# MCXA133 register map
Vendor: nxp.com; File version: 1.0
CPU: CM33 r2p0, little endian, no MPU, no FPU, VTOR, 3 interrupt priority bits
Registers are 32-bit, read-write, reset 0x0 unless marked. A register's access mark holds for its fields unless they carry their own. Offsets are from the block's base; [hi:lo] are bit positions; {n}, {i} and the like mark numbered series; 'fields as' and 'values as' point back to an identical list.

## MRCC0 — MRCC
Base 0x40091000
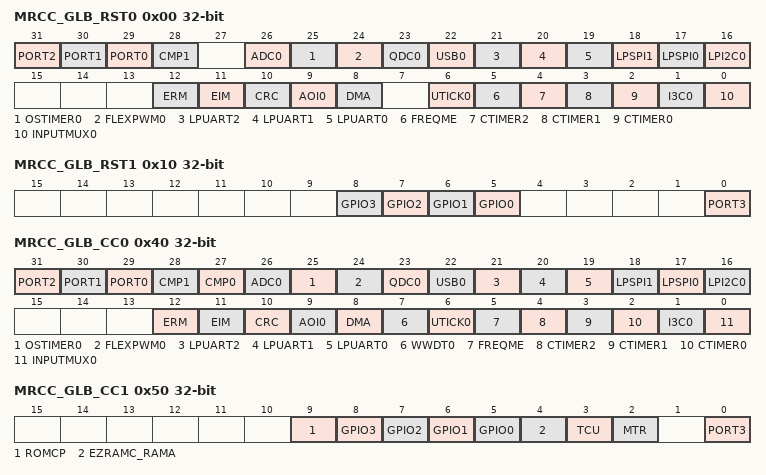
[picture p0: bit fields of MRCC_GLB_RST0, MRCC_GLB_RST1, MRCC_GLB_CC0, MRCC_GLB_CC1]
0x00 MRCC_GLB_RST0 — Peripheral Reset Control 0
  [all] fields
    0=DISABLED (Peripheral is held in reset); 1=ENABLED (Peripheral is released from reset)
  [31] PORT2 — Write to PORT2
  [30] PORT1 — Write to PORT1
  [29] PORT0 — Write to PORT0
  [28] CMP1 — Write to CMP1
  [26] ADC0 — Write to ADC0
  [25] OSTIMER0 — Write to OSTIMER0
  [24] FLEXPWM0 — Write to FLEXPWM0
  [23] QDC0 — Write to QDC0
  [22] USB0 — Write to USB0
  [21] LPUART2 — Write to LPUART2
  [20] LPUART1 — Write to LPUART1
  [19] LPUART0 — Write to LPUART0
  [18] LPSPI1 — Write to LPSPI1
  [17] LPSPI0 — Write to LPSPI0
  [16] LPI2C0 — Write to LPI2C0
  [12] ERM — Write to ERM
  [11] EIM — Write to EIM
  [10] CRC — Write to CRC
  [9] AOI0 — Write to AOI0
  [8] DMA — Write to DMA
  [6] UTICK0 — Write to UTICK0
  [5] FREQME — Write to FREQME
  [4] CTIMER2 — Write to CTIMER2
  [3] CTIMER1 — Write to CTIMER1
  [2] CTIMER0 — Write to CTIMER0
  [1] I3C0 — Write to I3C0
  [0] INPUTMUX0 — Write to INPUTMUX0
0x04 MRCC_GLB_RST0_SET wo — Peripheral Reset Control Set 0
  [31:0] DATA — Data array value, refer to corresponding position in MRCC_GLB_RSTn.
0x08 MRCC_GLB_RST0_CLR wo — Peripheral Reset Control Clear 0
  fields as MRCC_GLB_RST0_SET
0x10 MRCC_GLB_RST1 — Peripheral Reset Control 1
  [all] fields
    values as the fields of MRCC_GLB_RST0
  [n+5] GPIO{n} (n=0..3) — Write to GPIO{n}
  [0] PORT3 — Write to PORT3
0x14 MRCC_GLB_RST1_SET wo — Peripheral Reset Control Set 1
  fields as MRCC_GLB_RST0_SET
0x18 MRCC_GLB_RST1_CLR wo — Peripheral Reset Control Clear 1
  fields as MRCC_GLB_RST0_SET
0x40 MRCC_GLB_CC0 — AHB Clock Control 0
  [all] fields
    0=DISABLED (Peripheral clock is disabled); 1=ENABLED (Peripheral clock is enabled)
  [31] PORT2 — Write to PORT2
  [30] PORT1 — Write to PORT1
  [29] PORT0 — Write to PORT0
  [28] CMP1 — Write to CMP1
  [27] CMP0 — Write to CMP0
  [26] ADC0 — Write to ADC0
  [25] OSTIMER0 — Write to OSTIMER0
  [24] FLEXPWM0 — Write to FLEXPWM0
  [23] QDC0 — Write to QDC0
  [22] USB0 — Write to USB0
  [21] LPUART2 — Write to LPUART2
  [20] LPUART1 — Write to LPUART1
  [19] LPUART0 — Write to LPUART0
  [18] LPSPI1 — write to LPSPI1
  [17] LPSPI0 — Write to LPSPI0
  [16] LPI2C0 — Write to LPI2C0
  [12] ERM — Write to ERM
  [11] EIM — Write to EIM
  [10] CRC — Write to CRC
  [9] AOI0 — Write to AOI0
  [8] DMA — Write to DMA
  [7] WWDT0 — Write to WWDT0
  [6] UTICK0 — Write to UTICK0
  [5] FREQME — Write to FREQME
  [4] CTIMER2 — Write to CTIMER2
  [3] CTIMER1 — Write to CTIMER1
  [2] CTIMER0 — Write to CTIMER0
  [1] I3C0 — Write to I3C0
  [0] INPUTMUX0 — write to INPUTMUX0
0x44 MRCC_GLB_CC0_SET wo — AHB Clock Control Set 0
  [31:0] DATA — Data array value, refer to corresponding position in MRCC_GLB_CCn.
0x48 MRCC_GLB_CC0_CLR wo — AHB Clock Control Clear 0
  fields as MRCC_GLB_CC0_SET
0x50 MRCC_GLB_CC1 — AHB Clock Control 1
  [all] fields
    values as the fields of MRCC_GLB_CC0
  [9] ROMCP — Write to ROMCP
  [n+5] GPIO{n} (n=0..3) — Write to GPIO{n}
  [4] EZRAMC_RAMA — Write to EZRAMC_RAMA
  [3] TCU — Write to TCU
  [2] MTR — Write to MTR
  [0] PORT3 — Write to PORT3
0x54 MRCC_GLB_CC1_SET wo — AHB Clock Control Set 1
  fields as MRCC_GLB_CC0_SET
0x58 MRCC_GLB_CC1_CLR wo — AHB Clock Control Clear 1
  fields as MRCC_GLB_CC0_SET
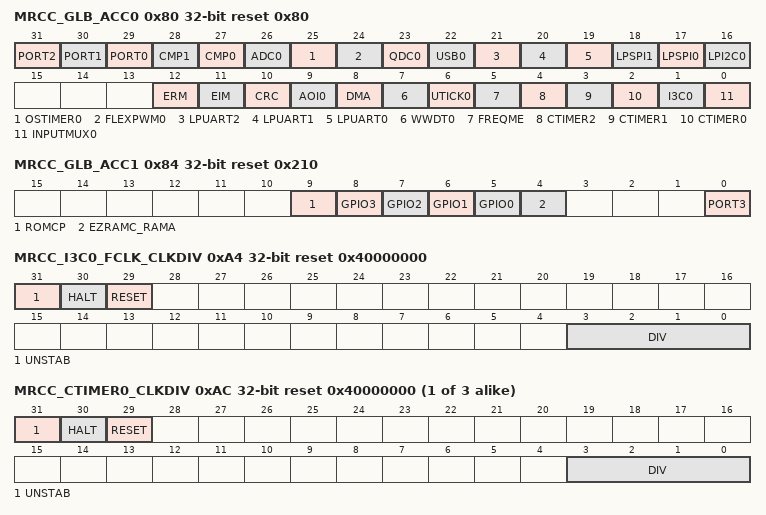
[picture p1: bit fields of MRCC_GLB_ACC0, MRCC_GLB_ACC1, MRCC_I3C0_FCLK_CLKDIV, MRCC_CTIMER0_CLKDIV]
0x80 MRCC_GLB_ACC0 reset 0x80 — Control Automatic Clock Gating 0
  [all] fields
    0=DISABLED (Automatic clock gating is disabled); 1=ENABLED (Automatic clock gating is enabled)
  [31] PORT2 — Write to PORT2
  [30] PORT1 — Write to PORT1
  [29] PORT0 — Write to PORT0
  [28] CMP1 — Write to CMP1
  [27] CMP0 — Write to CMP0
  [26] ADC0 — Write to ADC0
  [25] OSTIMER0 — Write to OSTIMER0
  [24] FLEXPWM0 — Write to FLEXPWM0
  [23] QDC0 — Write to QDC0
  [22] USB0 — Write to USB0
  [21] LPUART2 — Write to LPUART2
  [20] LPUART1 — Write to LPUART1
  [19] LPUART0 — Write to LPUART0
  [18] LPSPI1 — Write to LPSPI1
  [17] LPSPI0 — Write to LPSPI0
  [16] LPI2C0 — Write to LPI2C0
  [12] ERM — Write to ERM
  [11] EIM — Write to EIM
  [10] CRC — Write to CRC
  [9] AOI0 — Write to AOI0
  [8] DMA — Write to DMA
  [7] WWDT0 — Write to WWDT0
  [6] UTICK0 — Write to UTICK0
  [5] FREQME — Write to FREQME
  [4] CTIMER2 — Write to CTIMER2
  [3] CTIMER1 — Write to CTIMER1
  [2] CTIMER0 — Write to CTIMER0
  [1] I3C0 — Write to I3C0
  [0] INPUTMUX0 — Write to INPUTMUX0
0x84 MRCC_GLB_ACC1 reset 0x210 — Control Automatic Clock Gating 1
  [all] fields
    values as the fields of MRCC_GLB_ACC0
  [9] ROMCP — Write to ROMCP
  [n+5] GPIO{n} (n=0..3) — Write to GPIO{n}
  [4] EZRAMC_RAMA — Write to EZRAMC_RAMA
  [0] PORT3 — Write to PORT3
0xA0 MRCC_I3C0_FCLK_CLKSEL reset 0x7 — I3C0_FCLK clock selection control
  [2:0] MUX — Functional Clock Mux Select
    0=clkroot_func_0 (FRO_12M); 2=clkroot_func_2 (FRO_HF_DIV); 3=clkroot_func_3 (CLK_IN); 5=clkroot_func_5 (CLK_1M)
0xA4 MRCC_I3C0_FCLK_CLKDIV reset 0x40000000 — I3C0_FCLK clock divider control
  [31] UNSTAB ro — Divider status flag
    0=ON (Divider clock is stable); 1=OFF (Clock frequency isn't stable)
  [30] HALT — Halt divider counter
    0=ON (Divider clock is running); 1=OFF (Divider clock is stopped)
  [29] RESET wo — Reset divider counter
    0=ON (Divider isn't reset); 1=OFF (Divider is reset)
  [3:0] DIV — Functional Clock Divider
{0xA8+8i} MRCC_CTIMER{i}_CLKSEL reset 0x7 (i=0..2) — CTIMER{i} clock selection control
  [2:0] MUX — Functional Clock Mux Select
    0=clkroot_func_0 (FRO_12M); 1=clkroot_func_1 (FRO_HF_GATED); 3=clkroot_func_3 (CLK_IN); 4=clkroot_func_4 (CLK_16K); 5=clkroot_func_5 (CLK_1M)
{0xAC+8i} MRCC_CTIMER{i}_CLKDIV reset 0x40000000 (i=0..2) — CTIMER{i} clock divider control
  fields as MRCC_I3C0_FCLK_CLKDIV
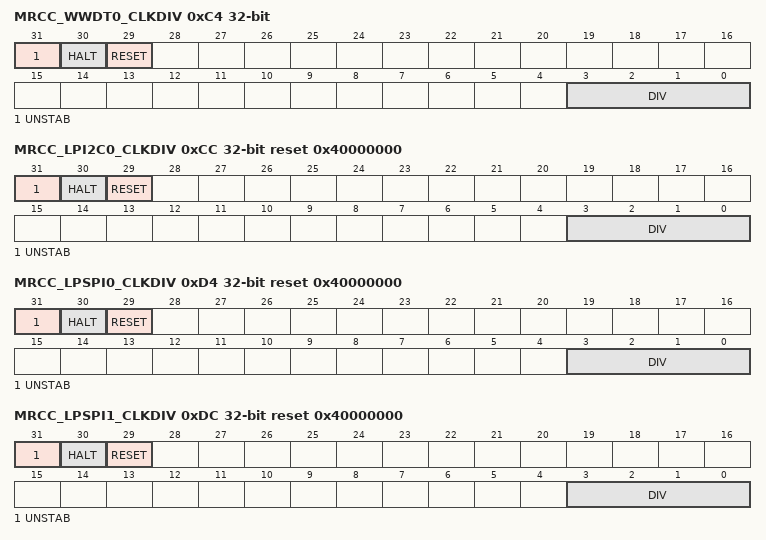
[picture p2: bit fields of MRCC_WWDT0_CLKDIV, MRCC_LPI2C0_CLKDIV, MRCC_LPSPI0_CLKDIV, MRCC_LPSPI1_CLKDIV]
0xC4 MRCC_WWDT0_CLKDIV — WWDT0 clock divider control
  fields as MRCC_I3C0_FCLK_CLKDIV
0xC8 MRCC_LPI2C0_CLKSEL reset 0x7 — LPI2C0 clock selection control
  fields as MRCC_I3C0_FCLK_CLKSEL
0xCC MRCC_LPI2C0_CLKDIV reset 0x40000000 — LPI2C0 clock divider control
  fields as MRCC_I3C0_FCLK_CLKDIV
0xD0 MRCC_LPSPI0_CLKSEL reset 0x7 — LPSPI0 clock selection control
  fields as MRCC_I3C0_FCLK_CLKSEL
0xD4 MRCC_LPSPI0_CLKDIV reset 0x40000000 — LPSPI0 clock divider control
  fields as MRCC_I3C0_FCLK_CLKDIV
0xD8 MRCC_LPSPI1_CLKSEL reset 0x7 — LPSPI1 clock selection control
  fields as MRCC_I3C0_FCLK_CLKSEL
0xDC MRCC_LPSPI1_CLKDIV reset 0x40000000 — LPSPI1 clock divider control
  fields as MRCC_I3C0_FCLK_CLKDIV
{0xE0+8i} MRCC_LPUART{i}_CLKSEL reset 0x7 (i=0..2) — LPUART{i} clock selection control
  [2:0] MUX — Functional Clock Mux Select
    0=clkroot_func_0 (FRO_12M); 2=clkroot_func_2 (FRO_HF_DIV); 3=clkroot_func_3 (CLK_IN); 4=clkroot_func_4 (CLK_16K); 5=clkroot_func_5 (CLK_1M)
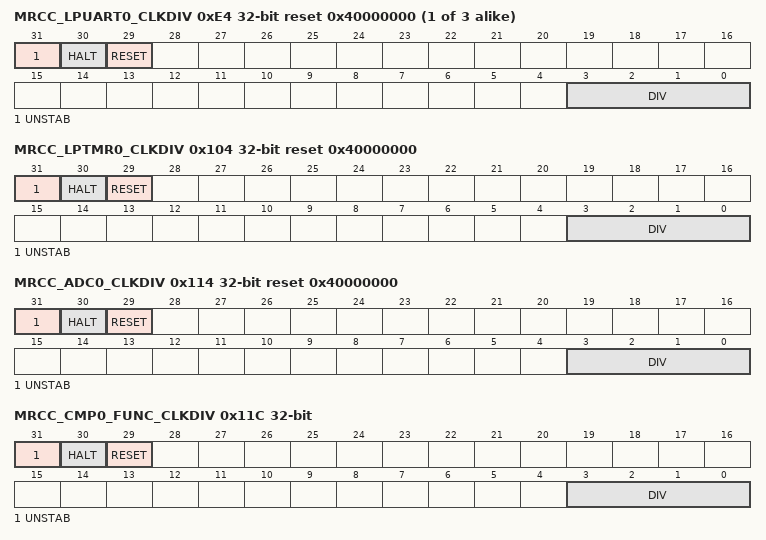
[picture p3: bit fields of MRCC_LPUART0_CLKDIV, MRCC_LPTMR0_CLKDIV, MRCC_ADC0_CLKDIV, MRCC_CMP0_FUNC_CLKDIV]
{0xE4+8i} MRCC_LPUART{i}_CLKDIV reset 0x40000000 (i=0..2) — LPUART{i} clock divider control
  fields as MRCC_I3C0_FCLK_CLKDIV
0xF8 MRCC_USB0_CLKSEL reset 0x3 — USB0 clock selection control
  [1:0] MUX — Functional Clock Mux Select
    1=scg_scg_firc_48mhz_clk; 2=clkroot_sosc
0x100 MRCC_LPTMR0_CLKSEL reset 0x7 — LPTMR0 clock selection control
  fields as MRCC_I3C0_FCLK_CLKSEL
0x104 MRCC_LPTMR0_CLKDIV reset 0x40000000 — LPTMR0 clock divider control
  fields as MRCC_I3C0_FCLK_CLKDIV
0x108 MRCC_OSTIMER0_CLKSEL reset 0x3 — OSTIMER0 clock selection control
  [1:0] MUX — Functional Clock Mux Select
    0=clkroot_16k; 2=clkroot_1m
0x110 MRCC_ADC0_CLKSEL reset 0x7 — ADC0 clock selection control
  [2:0] MUX — Functional Clock Mux Select
    0=clkroot_func_0 (FRO_12M); 1=clkroot_func_1 (FRO_HF_GATED); 3=clkroot_func_3 (CLK_IN); 5=clkroot_func_5 (CLK_1M)
0x114 MRCC_ADC0_CLKDIV reset 0x40000000 — ADC0 clock divider control
  fields as MRCC_I3C0_FCLK_CLKDIV
0x11C MRCC_CMP0_FUNC_CLKDIV — CMP0_FUNC clock divider control
  fields as MRCC_I3C0_FCLK_CLKDIV
0x120 MRCC_CMP0_RR_CLKSEL reset 0x7 — CMP0_RR clock selection control
  fields as MRCC_I3C0_FCLK_CLKSEL
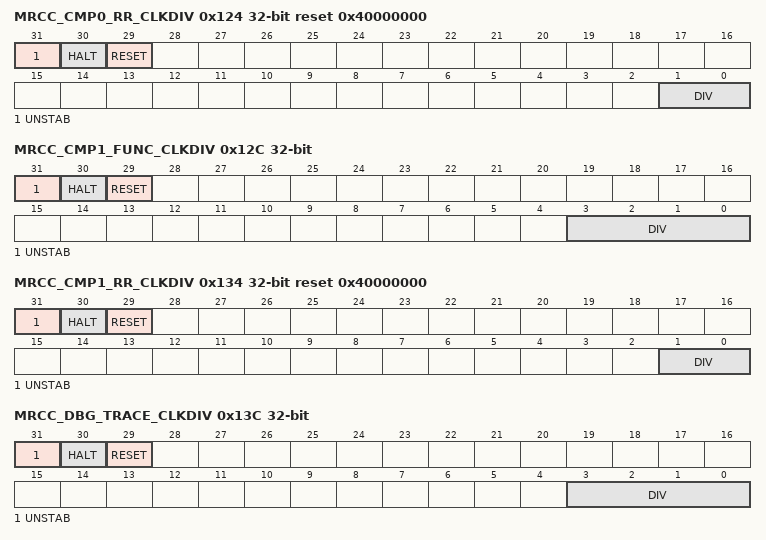
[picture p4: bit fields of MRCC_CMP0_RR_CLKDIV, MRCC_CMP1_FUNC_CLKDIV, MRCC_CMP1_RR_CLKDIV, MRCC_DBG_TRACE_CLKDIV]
0x124 MRCC_CMP0_RR_CLKDIV reset 0x40000000 — CMP0_RR clock divider control
  [31] UNSTAB ro — Divider status flag
    values as MRCC_I3C0_FCLK_CLKDIV.UNSTAB
  [30] HALT — Halt divider counter
    values as MRCC_I3C0_FCLK_CLKDIV.HALT
  [29] RESET wo — Reset divider counter
    0=ON (Divider isn't reset); 1=OFF (Divider is reset)
  [1:0] DIV — Functional Clock Divider
0x12C MRCC_CMP1_FUNC_CLKDIV — CMP1_FUNC clock divider control
  fields as MRCC_I3C0_FCLK_CLKDIV
0x130 MRCC_CMP1_RR_CLKSEL reset 0x7 — CMP1_RR clock selection control
  fields as MRCC_I3C0_FCLK_CLKSEL
0x134 MRCC_CMP1_RR_CLKDIV reset 0x40000000 — CMP1_RR clock divider control
  fields as MRCC_CMP0_RR_CLKDIV
0x138 MRCC_DBG_TRACE_CLKSEL — DBG_TRACE clock selection control
  [1:0] MUX — Functional Clock Mux Select
    0=clkroot_cpu; 1=clkroot_1m; 2=clkroot_16k
0x13C MRCC_DBG_TRACE_CLKDIV — DBG_TRACE clock divider control
  fields as MRCC_I3C0_FCLK_CLKDIV
0x140 MRCC_CLKOUT_CLKSEL reset 0x7 — CLKOUT clock selection control
  [2:0] MUX — Functional Clock Mux Select
    0=clkroot_12m; 1=clkroot_firc_div; 2=clkroot_sosc; 3=clkroot_16k; 6=clkroot_slow
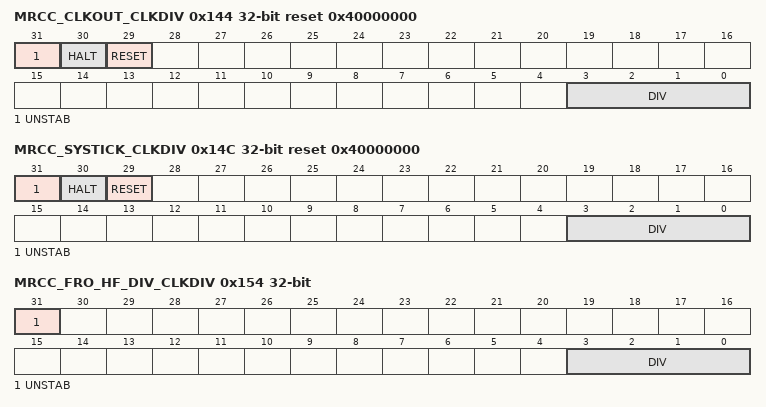
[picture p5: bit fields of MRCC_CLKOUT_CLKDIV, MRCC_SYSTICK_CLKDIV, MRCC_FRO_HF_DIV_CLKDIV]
0x144 MRCC_CLKOUT_CLKDIV reset 0x40000000 — CLKOUT clock divider control
  [31] UNSTAB ro — Divider status flag
    0=ON (Divider clock is stable); 1=OFF (Clock frequency is not stable)
  [30] HALT — Halt divider counter
    values as MRCC_I3C0_FCLK_CLKDIV.HALT
  [29] RESET wo — Reset divider counter
    0=ON (Divider isn't reset); 1=OFF (Divider is reset)
  [3:0] DIV — Functional Clock Divider
0x148 MRCC_SYSTICK_CLKSEL reset 0x3 — SYSTICK clock selection control
  fields as MRCC_DBG_TRACE_CLKSEL
0x14C MRCC_SYSTICK_CLKDIV reset 0x40000000 — SYSTICK clock divider control
  fields as MRCC_I3C0_FCLK_CLKDIV
0x154 MRCC_FRO_HF_DIV_CLKDIV — FRO_HF_DIV clock divider control
  [31] UNSTAB ro — Divider status flag
    values as MRCC_I3C0_FCLK_CLKDIV.UNSTAB
  [3:0] DIV — Functional Clock Divider
